# PY32F031xx register map
Vendor: Puya; Series: PY32F0; File version: 1.0.0
CPU: CM0+ r0p1, little endian, no MPU, no FPU, 4 interrupt priority bits
Registers are 32-bit, read-write, reset 0x0 unless marked. A register's access mark holds for its fields unless they carry their own. Offsets are from the block's base; [hi:lo] are bit positions; {n}, {i} and the like mark numbered series; 'fields as' and 'values as' point back to an identical list.

## SYSCFG — System configuration controller
Base 0x40010000
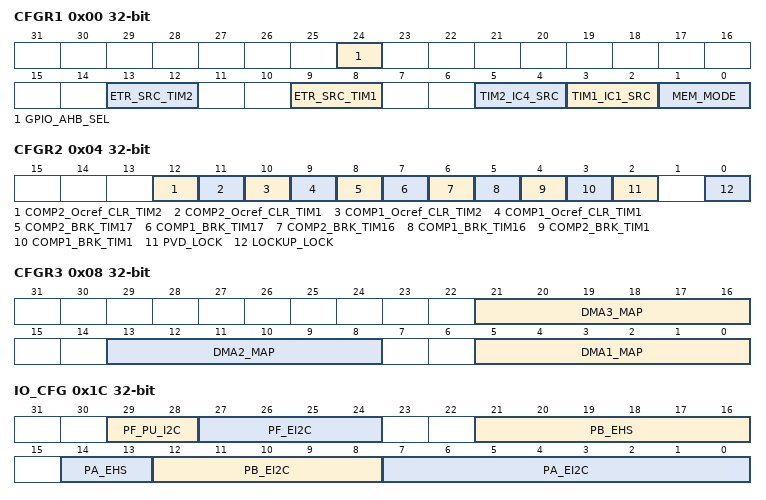
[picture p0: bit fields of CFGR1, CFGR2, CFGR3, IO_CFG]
0x00 CFGR1 — SYSCFG configuration register 1
  [24] GPIO_AHB_SEL
  [13:12] ETR_SRC_TIM2
  [9:8] ETR_SRC_TIM1
  [5:4] TIM2_IC4_SRC
  [3:2] TIM1_IC1_SRC
  [1:0] MEM_MODE — Memory mapping selection bits
0x04 CFGR2 — SYSCFG configuration register 2
  [12] COMP2_Ocref_CLR_TIM2
  [11] COMP2_Ocref_CLR_TIM1
  [10] COMP1_Ocref_CLR_TIM2
  [9] COMP1_Ocref_CLR_TIM1
  [8] COMP2_BRK_TIM17 — COMP2 is enable to input of TIM17 break
  [7] COMP1_BRK_TIM17 — COMP1 is enable to input of TIM17 break
  [6] COMP2_BRK_TIM16 — COMP2 is enable to input of TIM16 break
  [5] COMP1_BRK_TIM16 — COMP1 is enable to input of TIM16 break
  [4] COMP2_BRK_TIM1 — COMP2 is enable to input of TIM1 break
  [3] COMP1_BRK_TIM1 — COMP1 is enable to input of TIM1 break
  [2] PVD_LOCK — PVD lock enable bit
  [0] LOCKUP_LOCK — Cortex-M0+ LOCKUP bit enable bit
0x08 CFGR3 — SYSCFG configuration register 3
  [21:16] DMA3_MAP — DMA channel3 requeset selection
  [13:8] DMA2_MAP — DMA channel2 requeset selection
  [5:0] DMA1_MAP — DMA channel1 requeset selection
0x10 PA_ENS — GPIOA noise filter enable register
  [15:0] PA_ENS — Noise filter enable, active high
0x14 PB_ENS — GPIOB noise filter enable register
  [15:0] PB_ENS — Noise filter enable, active high
0x18 PF_ENS — GPIOF noise filter enable register
  [15:0] PF_ENS — Noise filter enable, active high
0x1C IO_CFG — I2C type IO configure register
  [29:28] PF_PU_I2C, [27:24] PF_EI2C, [21:16] PB_EHS, [14:13] PA_EHS, [12:8] PB_EI2C, [7:0] PA_EI2C
0x20 PA_ANA2EN — GPIOA Analog2 enable register
  [15:0] PA_ANA2EN — IO PORTA PAD_ANA2 enable
0x24 PB_ANA2EN — GPIOB Analog2 enable register
  [15:0] PB_ANA2EN — IO PORTB PAD_ANA2 enable
0x28 PF_ANA2EN — GPIOF Analog2 enable register
  [15:0] PF_ANA2EN — IO PORTF PAD_ANA2 enable

## DIV — Divider
Base 0x40023800
0x00 DEND — Dividend
0x04 SOR — Divisor
0x08 QUOT ro — Quotient
0x0C REMD ro — Remainder
0x10 SIGN — des SIGN
  [0] SIGN
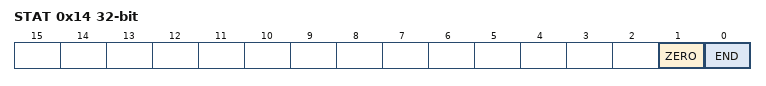
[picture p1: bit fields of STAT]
0x14 STAT — des SIGN
  [1] ZERO — des ZERO
  [0] END — des END

## CORDIC — Digital Co-process Operation
Base 0x40023400
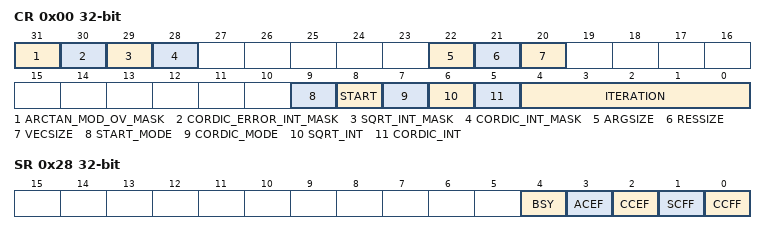
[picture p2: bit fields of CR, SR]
0x00 CR — CORDIC control register
  [31] ARCTAN_MOD_OV_MASK, [30] CORDIC_ERROR_INT_MASK, [29] SQRT_INT_MASK, [28] CORDIC_INT_MASK, [22] ARGSIZE, [21] RESSIZE, [20] VECSIZE, [9] START_MODE, [8] START, [7] CORDIC_MODE, [6] SQRT_INT, [5] CORDIC_INT, [4:0] ITERATION
0x04 THETA — SIN or COS input theta register
0x08 SIN ro — CORDIC SIN result register
  [23:0] SIN — SIN result
0x0C COS ro — CORDIC COS result register
  [23:0] COS — COS result
0x10 X — Arctan input coordinate register
  [23:0] X — arctan or module X register
0x14 Y — Arctan input coordinate register
  [23:0] Y — arctan or module Y register
0x18 MOD ro — CORDIC Mod result register
  [24:0] MOD — mod result
0x1C ARCTAN ro — CORDIC ARCTAN result register
  [15:0] ARCTAN — arctan result
0x20 DSP_RAD — CORDIC Radicand register
  [31:0] RAD — Number of open parties
0x24 DSP_SQRT ro — CORDIC SQRT result register
  [15:0] SQRT — sqrt result
0x28 SR ro — CORDIC Status register
  [4] BSY
  [3] ACEF — desc ACFF
  [2] CCEF — desc CCFF
  [1] SCFF
  [0] CCFF

## DMA — Direct memory access
Base 0x40020000
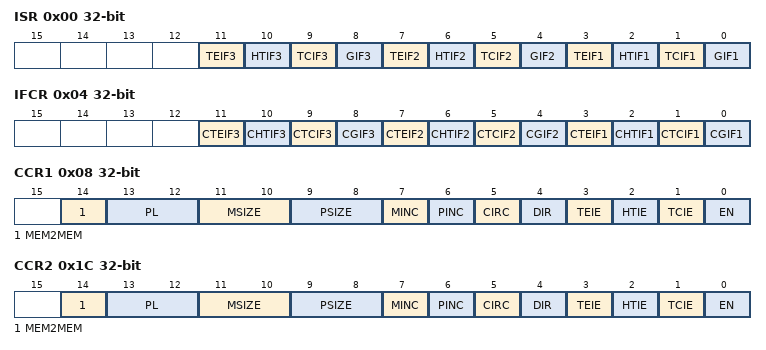
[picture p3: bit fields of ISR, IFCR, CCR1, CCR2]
0x00 ISR ro — DMA interrupt status register (DMA_ISR)
  [11] TEIF3 — Channel 3 Transfer Error flag
  [10] HTIF3 — Channel 3 Half Transfer Complete flag
  [9] TCIF3 — Channel 3 Transfer Complete flag
  [8] GIF3 — Channel 3 Global interrupt flag
  [7] TEIF2 — Channel 2 Transfer Error flag
  [6] HTIF2 — Channel 2 Half Transfer Complete flag
  [5] TCIF2 — Channel 2 Transfer Complete flag
  [4] GIF2 — Channel 2 Global interrupt flag
  [3] TEIF1 — Channel 1 Transfer Error flag
  [2] HTIF1 — Channel 1 Half Transfer Complete flag
  [1] TCIF1 — Channel 1 Transfer Complete flag
  [0] GIF1 — Channel 1 Global interrupt flag
0x04 IFCR wo — DMA interrupt flag clear register (DMA_IFCR)
  [11] CTEIF3 — Channel 3 Transfer Error clear
  [10] CHTIF3 — Channel 3 Half Transfer clear
  [9] CTCIF3 — Channel 3 Transfer Complete clear
  [8] CGIF3 — Channel 3 Global interrupt clear
  [7] CTEIF2 — Channel 2 Transfer Error clear
  [6] CHTIF2 — Channel 2 Half Transfer clear
  [5] CTCIF2 — Channel 2 Transfer Complete clear
  [4] CGIF2 — Channel 2 Global interrupt clear
  [3] CTEIF1 — Channel 1 Transfer Error clear
  [2] CHTIF1 — Channel 1 Half Transfer clear
  [1] CTCIF1 — Channel 1 Transfer Complete clear
  [0] CGIF1 — Channel 1 Global interrupt clear
0x08 CCR1 — DMA channel configuration register (DMA_CCR)
  [14] MEM2MEM — Memory to memory mode
  [13:12] PL — Channel Priority level
  [11:10] MSIZE — Memory size
  [9:8] PSIZE — Peripheral size
  [7] MINC — Memory increment mode
  [6] PINC — Peripheral increment mode
  [5] CIRC — Circular mode
  [4] DIR — Data transfer direction
  [3] TEIE — Transfer error interrupt enable
  [2] HTIE — Half Transfer interrupt enable
  [1] TCIE — Transfer complete interrupt enable
  [0] EN — Channel enable
0x0C CNDTR1 — DMA channel 1 number of data register
  [15:0] NDT — Number of data to transfer
0x10 CPAR1 — DMA channel 1 peripheral address register
  [31:0] PA — Peripheral address
{0x0+0x14*i} CMAR{i} (i=1..3) — DMA channel {i} memory address register
  [31:0] MA — Memory address
0x1C CCR2 — DMA channel configuration register (DMA_CCR)
  fields as CCR1
0x20 CNDTR2 — DMA channel 2 number of data register
  [15:0] NDT — Number of data to transfer
0x24 CPAR2 — DMA channel 2 peripheral address register
  [31:0] PA — Peripheral address
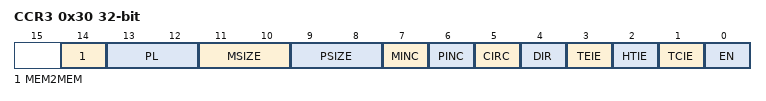
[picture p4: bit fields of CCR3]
0x30 CCR3 — DMA channel configuration register (DMA_CCR)
  fields as CCR1
0x34 CNDTR3 — DMA channel 3 number of data register
  [15:0] NDT — Number of data to transfer
0x38 CPAR3 — DMA channel 3 peripheral address register
  [31:0] PA — Peripheral address
